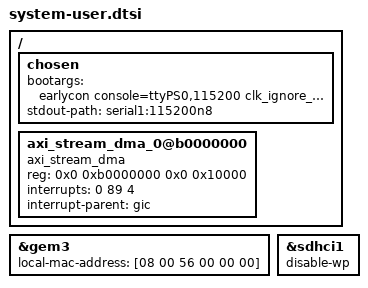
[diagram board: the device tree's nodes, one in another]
/include/ "system-conf.dtsi"
/ {
	chosen {
		bootargs = " earlycon console=ttyPS0,115200 clk_ignore_unused root=/dev/ram0 rw init_fatal_sh=1 cma=900M ";
		stdout-path = "serial1:115200n8";
	};
};
&gem3 {
	local-mac-address = [08 00 56 00 00 00];
};
&sdhci1 {
	disable-wp;
};
/ {
	axi_stream_dma_0@b0000000 {
		compatible = "axi_stream_dma";
		reg = <0x0 0xb0000000 0x0 0x10000>;
		interrupts = <0 89 4>;
		interrupt-parent = <&gic>;
	};
};
